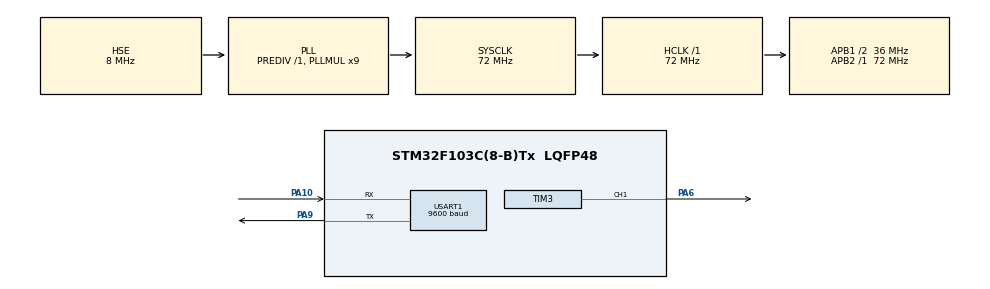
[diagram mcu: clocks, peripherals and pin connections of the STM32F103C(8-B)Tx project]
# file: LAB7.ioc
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Mcu.Family=STM32F1
Mcu.Name=STM32F103C(8-B)Tx
Mcu.Package=LQFP48
NVIC.PriorityGroup=NVIC_PRIORITYGROUP_4
NVIC.TIM2_IRQn=true\:7\:0\:true\:false\:true\:true\:true\:true
NVIC.TIM3_IRQn=true\:5\:0\:true\:false\:true\:true\:true\:true
NVIC.USART1_IRQn=true\:7\:0\:true\:false\:true\:true\:true\:true
PA10.Mode=Asynchronous
PA10.Signal=USART1_RX
PA13.Mode=Serial_Wire
PA13.Signal=SYS_JTMS-SWDIO
PA14.Mode=Serial_Wire
PA14.Signal=SYS_JTCK-SWCLK
PA6.Signal=S_TIM3_CH1
PA9.Mode=Asynchronous
PA9.Signal=USART1_TX
PD0-OSC_IN.Mode=HSE-External-Oscillator
PD0-OSC_IN.Signal=RCC_OSC_IN
PD1-OSC_OUT.Mode=HSE-External-Oscillator
PD1-OSC_OUT.Signal=RCC_OSC_OUT
ProjectManager.HeapSize=0x200
ProjectManager.StackSize=0x400
ProjectManager.TargetToolchain=STM32CubeIDE
RCC.AHBFreq_Value=72000000
RCC.APB1CLKDivider=RCC_HCLK_DIV2
RCC.APB1Freq_Value=36000000
RCC.APB1TimFreq_Value=72000000
RCC.APB2Freq_Value=72000000
RCC.APB2TimFreq_Value=72000000
RCC.HCLKFreq_Value=72000000
RCC.PLLMUL=RCC_PLL_MUL9
RCC.PLLSourceVirtual=RCC_PLLSOURCE_HSE
RCC.SYSCLKFreq_VALUE=72000000
RCC.SYSCLKSource=RCC_SYSCLKSOURCE_PLLCLK
RCC.USBFreq_Value=72000000
SH.S_TIM3_CH1.0=TIM3_CH1,PWM Generation1 CH1
TIM2.Period=1000
TIM2.Prescaler=7199
TIM3.Channel-PWM\ Generation1\ CH1=TIM_CHANNEL_1
TIM3.Period=100
USART1.BaudRate=9600
USART1.VirtualMode=VM_ASYNC
VP_TIM2_VS_ClockSourceINT.Mode=Internal
VP_TIM3_VS_ClockSourceINT.Mode=Internal
board=custom

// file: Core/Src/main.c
/* USER CODE BEGIN Header */
/**
  ******************************************************************************
  * @file           : main.c
  * @brief          : Main program body
  ******************************************************************************
  * @attention
  *
  * Copyright (c) 2022 STMicroelectronics.
  * All rights reserved.
  *
  * This software is licensed under terms that can be found in the LICENSE file
  * in the root directory of this software component.
  * If no LICENSE file comes with this software, it is provided AS-IS.
  *
  ******************************************************************************
  */
/* USER CODE END Header */
#include "main.h"

/* USER CODE BEGIN PTD */
/*** MAQUINA DE ESTADOS ***/
typedef enum {FSM_RESET, FSM_APAGADO, FSM_CONTANDO, FSM_PAUSADO} estados_t;
typedef enum {FSM_START_STOP, FSM_PAUSE, FSM_100ms} eventos_t;
volatile estados_t estado_actual = FSM_RESET;
/*** RECEPCIÓN UART ***/
volatile uint8_t buffer;

#define NX 50
// período de sinusoide de 50 muestras entre 0 y 100 de amplitud
const uint8_t x[NX] = {50,56,62,68,74,79,84,89,92,95,98,99,100,100,99,98,95,92,89,84,79, 74,68,62,56,50,44,38,32,26,21,16,11,8,5,2,1,0,0,1,2,5,8,11,16,21,26,32,38,44};
volatile uint16_t i=0;
volatile uint8_t volumen = 100;
volatile uint32_t count_pulses = 0;

/* USER CODE END PTD */

TIM_HandleTypeDef htim2;
TIM_HandleTypeDef htim3;

UART_HandleTypeDef huart1;

void SystemClock_Config(void);
static void MX_GPIO_Init(void);
static void MX_TIM2_Init(void);
static void MX_USART1_UART_Init(void);
static void MX_TIM3_Init(void);
/* USER CODE BEGIN PFP */
void fsm_cronometro(estados_t *actual, eventos_t evento);
void HAL_TIM_PeriodElapsedCallback(TIM_HandleTypeDef *htim);
void HAL_UART_RxCpltCallback(UART_HandleTypeDef *huart);
int _write(int file, char *ptr, int len);
/*beep*/
void Beep(uint16_t ms);
void HAL_TIM_OC_DelayElapsedCallback(TIM_HandleTypeDef *htim);
/* USER CODE END PFP */

int main(void)
{

  /* MCU Configuration--------------------------------------------------------*/

  /* Reset of all peripherals, Initializes the Flash interface and the Systick. */
  HAL_Init();

  /* Configure the system clock */
  SystemClock_Config();

  /* Initialize all configured peripherals */
  MX_GPIO_Init();
  MX_TIM2_Init();
  MX_USART1_UART_Init();
  MX_TIM3_Init();
  /* USER CODE BEGIN 2 */
	HAL_TIM_Base_Start_IT(&htim2);
	HAL_UART_Receive_IT(&huart1, (uint8_t*)&buffer, 1);
	fsm_cronometro((estados_t*)&estado_actual, -1);

  /* USER CODE END 2 */

  /* Infinite loop */
  while (1)
  {

  }
}

void SystemClock_Config(void)
{
  RCC_OscInitTypeDef RCC_OscInitStruct = {0};
  RCC_ClkInitTypeDef RCC_ClkInitStruct = {0};

  /** Initializes the RCC Oscillators according to the specified parameters
  * in the RCC_OscInitTypeDef structure.
  */
  RCC_OscInitStruct.OscillatorType = RCC_OSCILLATORTYPE_HSE;
  RCC_OscInitStruct.HSEState = RCC_HSE_ON;
  RCC_OscInitStruct.HSEPredivValue = RCC_HSE_PREDIV_DIV1;
  RCC_OscInitStruct.HSIState = RCC_HSI_ON;
  RCC_OscInitStruct.PLL.PLLState = RCC_PLL_ON;
  RCC_OscInitStruct.PLL.PLLSource = RCC_PLLSOURCE_HSE;
  RCC_OscInitStruct.PLL.PLLMUL = RCC_PLL_MUL9;
  if (HAL_RCC_OscConfig(&RCC_OscInitStruct) != HAL_OK)
  {
    Error_Handler();
  }

  /** Initializes the CPU, AHB and APB buses clocks
  */
  RCC_ClkInitStruct.ClockType = RCC_CLOCKTYPE_HCLK|RCC_CLOCKTYPE_SYSCLK
                              |RCC_CLOCKTYPE_PCLK1|RCC_CLOCKTYPE_PCLK2;
  RCC_ClkInitStruct.SYSCLKSource = RCC_SYSCLKSOURCE_PLLCLK;
  RCC_ClkInitStruct.AHBCLKDivider = RCC_SYSCLK_DIV1;
  RCC_ClkInitStruct.APB1CLKDivider = RCC_HCLK_DIV2;
  RCC_ClkInitStruct.APB2CLKDivider = RCC_HCLK_DIV1;

  if (HAL_RCC_ClockConfig(&RCC_ClkInitStruct, FLASH_LATENCY_2) != HAL_OK)
  {
    Error_Handler();
  }
}

static void MX_TIM2_Init(void)
{

  TIM_ClockConfigTypeDef sClockSourceConfig = {0};
  TIM_MasterConfigTypeDef sMasterConfig = {0};

  htim2.Instance = TIM2;
  htim2.Init.Prescaler = 7199;
  htim2.Init.CounterMode = TIM_COUNTERMODE_UP;
  htim2.Init.Period = 1000;
  htim2.Init.ClockDivision = TIM_CLOCKDIVISION_DIV1;
  htim2.Init.AutoReloadPreload = TIM_AUTORELOAD_PRELOAD_DISABLE;
  if (HAL_TIM_Base_Init(&htim2) != HAL_OK)
  {
    Error_Handler();
  }
  sClockSourceConfig.ClockSource = TIM_CLOCKSOURCE_INTERNAL;
  if (HAL_TIM_ConfigClockSource(&htim2, &sClockSourceConfig) != HAL_OK)
  {
    Error_Handler();
  }
  sMasterConfig.MasterOutputTrigger = TIM_TRGO_RESET;
  sMasterConfig.MasterSlaveMode = TIM_MASTERSLAVEMODE_DISABLE;
  if (HAL_TIMEx_MasterConfigSynchronization(&htim2, &sMasterConfig) != HAL_OK)
  {
    Error_Handler();
  }

}

static void MX_TIM3_Init(void)
{

  TIM_ClockConfigTypeDef sClockSourceConfig = {0};
  TIM_MasterConfigTypeDef sMasterConfig = {0};
  TIM_OC_InitTypeDef sConfigOC = {0};

  htim3.Instance = TIM3;
  htim3.Init.Prescaler = 0;
  htim3.Init.CounterMode = TIM_COUNTERMODE_UP;
  htim3.Init.Period = 100;
  htim3.Init.ClockDivision = TIM_CLOCKDIVISION_DIV1;
  htim3.Init.AutoReloadPreload = TIM_AUTORELOAD_PRELOAD_DISABLE;
  if (HAL_TIM_Base_Init(&htim3) != HAL_OK)
  {
    Error_Handler();
  }
  sClockSourceConfig.ClockSource = TIM_CLOCKSOURCE_INTERNAL;
  if (HAL_TIM_ConfigClockSource(&htim3, &sClockSourceConfig) != HAL_OK)
  {
    Error_Handler();
  }
  if (HAL_TIM_PWM_Init(&htim3) != HAL_OK)
  {
    Error_Handler();
  }
  sMasterConfig.MasterOutputTrigger = TIM_TRGO_RESET;
  sMasterConfig.MasterSlaveMode = TIM_MASTERSLAVEMODE_DISABLE;
  if (HAL_TIMEx_MasterConfigSynchronization(&htim3, &sMasterConfig) != HAL_OK)
  {
    Error_Handler();
  }
  sConfigOC.OCMode = TIM_OCMODE_PWM1;
  sConfigOC.Pulse = 0;
  sConfigOC.OCPolarity = TIM_OCPOLARITY_HIGH;
  sConfigOC.OCFastMode = TIM_OCFAST_DISABLE;
  if (HAL_TIM_PWM_ConfigChannel(&htim3, &sConfigOC, TIM_CHANNEL_1) != HAL_OK)
  {
    Error_Handler();
  }
  HAL_TIM_MspPostInit(&htim3);

}

static void MX_USART1_UART_Init(void)
{

  huart1.Instance = USART1;
  huart1.Init.BaudRate = 9600;
  huart1.Init.WordLength = UART_WORDLENGTH_8B;
  huart1.Init.StopBits = UART_STOPBITS_1;
  huart1.Init.Parity = UART_PARITY_NONE;
  huart1.Init.Mode = UART_MODE_TX_RX;
  huart1.Init.HwFlowCtl = UART_HWCONTROL_NONE;
  huart1.Init.OverSampling = UART_OVERSAMPLING_16;
  if (HAL_UART_Init(&huart1) != HAL_OK)
  {
    Error_Handler();
  }

}

static void MX_GPIO_Init(void)
{

  /* GPIO Ports Clock Enable */
  __HAL_RCC_GPIOD_CLK_ENABLE();
  __HAL_RCC_GPIOA_CLK_ENABLE();

}

/* USER CODE BEGIN 4 */
void HAL_TIM_PeriodElapsedCallback(TIM_HandleTypeDef *htim) {
	fsm_cronometro((estados_t*)&estado_actual, FSM_100ms);
}
void HAL_UART_RxCpltCallback(UART_HandleTypeDef *huart) {
	switch (buffer) {
	case 'S':
	case 's':
	fsm_cronometro((estados_t*)&estado_actual, FSM_START_STOP);
	break;
	case 'P':
	case 'p':
	fsm_cronometro((estados_t*)&estado_actual, FSM_PAUSE);
	break;
	}
	HAL_UART_Receive_IT(&huart1, (uint8_t*)&buffer, 1);
}
void fsm_cronometro(estados_t *actual, eventos_t evento) {
	static uint8_t h = 0, m = 0, s = 0, ds = 0;
	volatile estados_t anterior = *actual;
	switch (anterior) {
	case FSM_RESET:
		*actual = FSM_APAGADO;
		break;
	case FSM_APAGADO:
		if (evento == FSM_START_STOP)
			*actual = FSM_CONTANDO;
		break;
	case FSM_CONTANDO:
		switch (evento) {
		case FSM_START_STOP:
			*actual = FSM_APAGADO;
			break;
		case FSM_PAUSE:
			*actual = FSM_PAUSADO;
			break;
		case FSM_100ms:
			ds++;
			if (ds > 9) {
				Beep(500);
				ds = 0;
				s++;
			}
			if (s > 59) {
				s = 0;
				m++;
			}
			if (m > 59) {
				m = 0;
				h++;
			}
			if (h > 23) {
				h = 0;
			}
			printf("%02d:%02d:%02d.%d\r\n", h, m, s, ds);
			break;
		}
		break;
	case FSM_PAUSADO:
		switch (evento) {
		case FSM_100ms:
			break;
		case FSM_PAUSE:
			*actual = FSM_CONTANDO;
			break;
		case FSM_START_STOP:
			*actual = FSM_APAGADO;
			break;
		}
		break;
	}
	//acciones tipo Moore
	if (*actual != anterior) {
		if (*actual == FSM_APAGADO) {
			h = m = s = ds = 0;
			printf("%02d:%02d:%02d.%d\r\n", h, m, s, ds);
		}
	}
}
int _write(int file, char *ptr, int len) {
	HAL_UART_Transmit(&huart1, ptr, len, HAL_MAX_DELAY);
	return len;
}
//LAB HOY
void Beep(uint16_t ms) {
	count_pulses = ms * 80;
	HAL_TIM_PWM_Start_IT(&htim3, TIM_CHANNEL_1);
}
void HAL_TIM_OC_DelayElapsedCallback(TIM_HandleTypeDef *htim) {
	TIM3->CCR1 = x[i];
	i++;
	if (i >= NX)
		i = 0;
	count_pulses--;
	if (count_pulses == 0)
		HAL_TIM_PWM_Stop_IT(&htim3, TIM_CHANNEL_1);
}

/* USER CODE END 4 */

void Error_Handler(void)
{
  __disable_irq();
  while (1)
  {
  }
}
